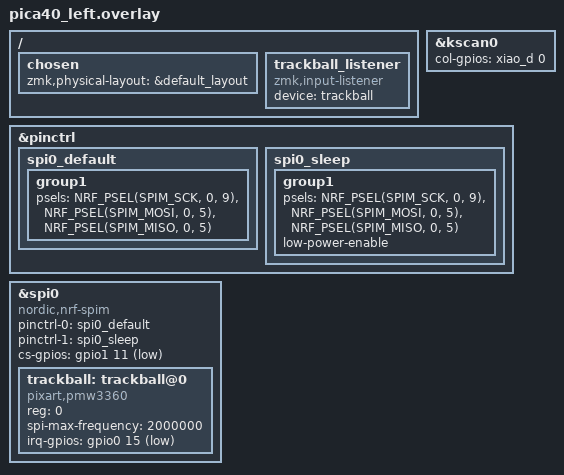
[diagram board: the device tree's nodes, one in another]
#include "pica40.dtsi"

&kscan0 {
    col-gpios
        = <&xiao_d 0 GPIO_ACTIVE_HIGH>
        ;
};

/ {
    chosen {
        zmk,physical-layout = &default_layout;
    };
};

&pinctrl {
    spi0_default: spi0_default {
        group1 {
            psels = <NRF_PSEL(SPIM_SCK, 0, 9)>,
                <NRF_PSEL(SPIM_MOSI, 0, 5)>,
                <NRF_PSEL(SPIM_MISO, 0, 5)>;
        };
    };

    spi0_sleep: spi0_sleep {
        group1 {
            psels = <NRF_PSEL(SPIM_SCK, 0, 9)>,
                <NRF_PSEL(SPIM_MOSI, 0, 5)>,
                <NRF_PSEL(SPIM_MISO, 0, 5)>;
            low-power-enable;
        };
    };
};

&spi0 {
    status = "okay";
    compatible = "nordic,nrf-spim";
    pinctrl-0 = <&spi0_default>;
    pinctrl-1 = <&spi0_sleep>;
    pinctrl-names = "default", "sleep";
    cs-gpios = <&gpio1 11 GPIO_ACTIVE_LOW>;

    trackball: trackball@0 {
        status = "okay";
        compatible = "pixart,pmw3360";
        reg = <0>;
        spi-max-frequency = <2000000>;
        irq-gpios = <&gpio0 15 (GPIO_ACTIVE_LOW | GPIO_PULL_UP)>;
    };
};

/ {
  trackball_listener {
    compatible = "zmk,input-listener";
    device = <&trackball>;

  };
};
